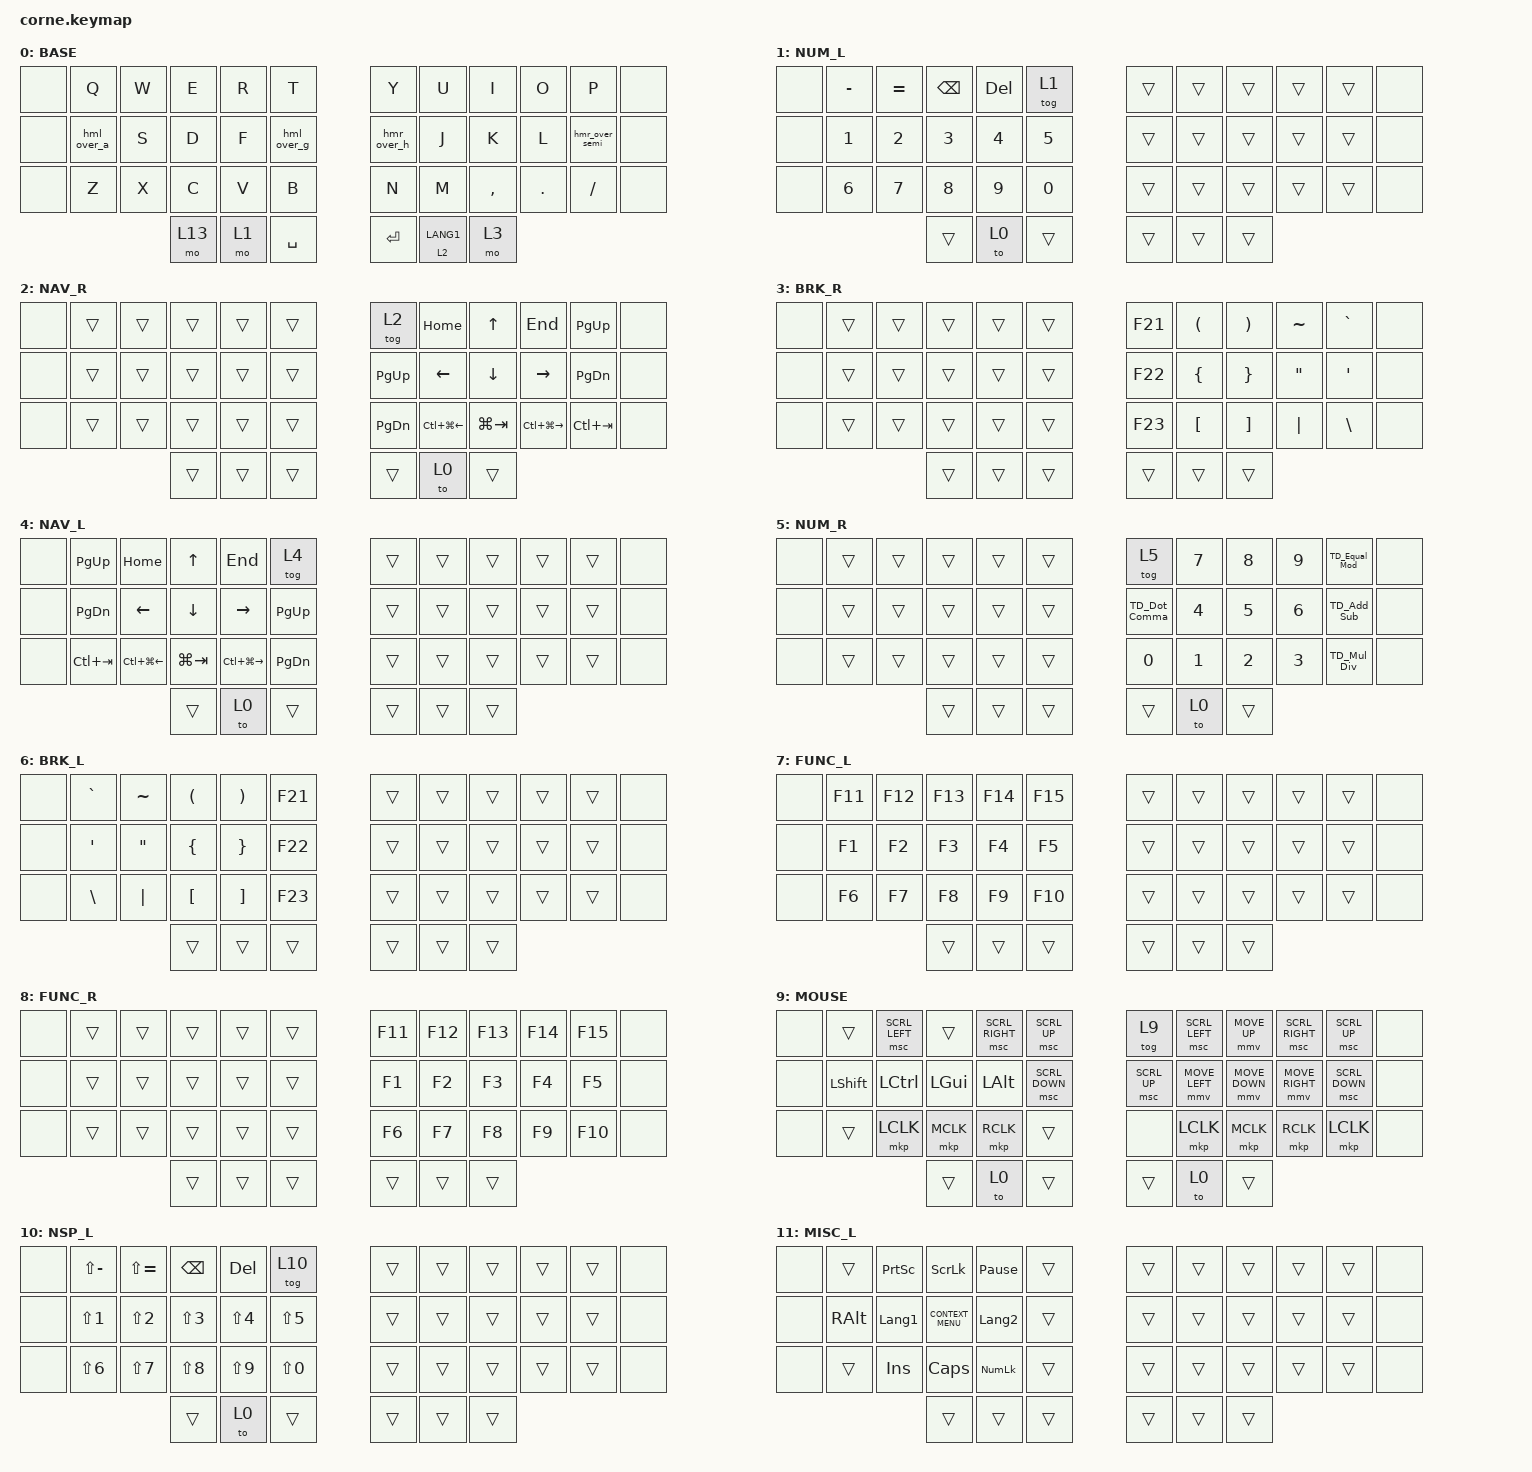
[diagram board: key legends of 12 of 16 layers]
/*
 * Copyright (c) 2020 The ZMK Contributors
 *
 * SPDX-License-Identifier: MIT
 */

#include <behaviors.dtsi>
#include <dt-bindings/zmk/bt.h>
#include <dt-bindings/zmk/ext_power.h>
#include <dt-bindings/zmk/keys.h>
#include <dt-bindings/zmk/outputs.h>
#include <dt-bindings/zmk/pointing.h>

&mt {
    flavor = "balanced";
    quick-tap-ms = <175>;
};

&lt {
    flavor = "hold-preferred";
    tapping-term-ms = <180>;
    hold-while-undecided;
};

&tog { toggle-mode = "on"; };

/ {
    combos {
        compatible = "zmk,combos";

        CAPS_L {
            bindings = <&kp CAPSLOCK>;
            key-positions = <27 37>;
            layers = <0>;
            require-prior-idle-ms = <0>;
            timeout-ms = <30>;
        };

        TAB_L {
            bindings = <&kp TAB>;
            key-positions = <17 38>;
            layers = <0>;
            require-prior-idle-ms = <0>;
            timeout-ms = <30>;
        };

        ENTER_L {
            bindings = <&kp ENTER>;
            key-positions = <5 38>;
            layers = <0>;
            require-prior-idle-ms = <0>;
            timeout-ms = <30>;
        };

        ESC_L {
            bindings = <&kp ESCAPE>;
            key-positions = <37 2>;
            layers = <0>;
            require-prior-idle-ms = <0>;
            timeout-ms = <30>;
        };

        VOL_UP_L {
            bindings = <&kp C_VOLUME_UP>;
            key-positions = <37 5>;
            layers = <0>;
            require-prior-idle-ms = <200>;
            timeout-ms = <30>;
        };

        VOL_DN_L {
            bindings = <&kp C_VOLUME_DOWN>;
            key-positions = <37 17>;
            layers = <0>;
            require-prior-idle-ms = <200>;
            timeout-ms = <30>;
        };

        LCtrl_L {
            bindings = <&kp LEFT_CONTROL>;
            key-positions = <14 15>;
            layers = <0>;
            slow-release;
            require-prior-idle-ms = <70>;
            timeout-ms = <30>;
        };

        LAlt_L {
            bindings = <&kp LEFT_ALT>;
            key-positions = <16 17>;
            layers = <0>;
            slow-release;
            require-prior-idle-ms = <70>;
            timeout-ms = <30>;
        };

        LGUI_L {
            bindings = <&kp LEFT_GUI>;
            key-positions = <16 15>;
            layers = <0>;
            slow-release;
            require-prior-idle-ms = <70>;
            timeout-ms = <30>;
        };

        MO_FUNC_L {
            bindings = <&mo 7>;
            key-positions = <37 16>;
            layers = <0 2 3 5 8 12>;
            slow-release;
            require-prior-idle-ms = <0>;
            timeout-ms = <30>;
        };

        MO_FUNC_R {
            bindings = <&mo 8>;
            key-positions = <40 19>;
            layers = <0 1 4 6 7 10 11>;
            slow-release;
            require-prior-idle-ms = <0>;
            timeout-ms = <30>;
        };

        MO_NAV_L {
            bindings = <&mo 4>;
            key-positions = <15 37>;
            layers = <0 2 3 5 8 12>;
            slow-release;
            require-prior-idle-ms = <0>;
            timeout-ms = <30>;
        };

        MO_NUM_R {
            bindings = <&mo 5>;
            key-positions = <40 20>;
            layers = <0 1 4 6 7 10 11>;
            slow-release;
            timeout-ms = <30>;
        };

        MO_MISC_L {
            bindings = <&mo 11>;
            key-positions = <37 14>;
            layers = <0 2 3 5 8 12>;
            slow-release;
            require-prior-idle-ms = <0>;
            timeout-ms = <30>;
        };

        MO_MISC_R {
            bindings = <&mo 12>;
            key-positions = <40 21>;
            layers = <0 1 4 6 7 10 11>;
            slow-release;
            require-prior-idle-ms = <0>;
            timeout-ms = <30>;
        };

        MO_BRK_L {
            bindings = <&mo 6>;
            key-positions = <37 29>;
            layers = <0 2 3 5 8 12>;
            slow-release;
            require-prior-idle-ms = <0>;
            timeout-ms = <30>;
        };

        MO_NUMSP_L {
            bindings = <&mo 10>;
            key-positions = <37 28>;
            layers = <0 2 3 5 8 12>;
            slow-release;
            require-prior-idle-ms = <0>;
            timeout-ms = <30>;
        };

        MO_MOUSE {
            bindings = <&mo 9>;
            key-positions = <40 31>;
            layers = <0>;
            slow-release;
            require-prior-idle-ms = <200>;
            timeout-ms = <30>;
        };

        TO_BASE_L {
            bindings = <&to 0>;
            key-positions = <38 37 36>;
            timeout-ms = <30>;
        };

        MO_SETTING {
            bindings = <&mo 14>;
            key-positions = <14 3 5 37>;
            require-prior-idle-ms = <0>;
            slow-release;
            timeout-ms = <30>;
        };

        bootload {
            bindings = <&bootloader>;
            key-positions = <5 29 29>;
            layers = <14>;
        };

        sysreset {
            bindings = <&sys_reset>;
            key-positions = <4 14>;
            layers = <14>;
        };

        LCTRL_SHFT_L {
            bindings = <&kp LC(LEFT_SHIFT)>;
            key-positions = <14 13>;
            slow-release;
            layers = <0>;
            require-prior-idle-ms = <70>;
            timeout-ms = <30>;
        };

        LALT_SHFT_L {
            bindings = <&kp LA(LEFT_SHIFT)>;
            key-positions = <13 16>;
            slow-release;
            layers = <0>;
            require-prior-idle-ms = <70>;
            timeout-ms = <30>;
        };

        LCTRL_ALT_L {
            bindings = <&kp LC(LEFT_ALT)>;
            key-positions = <14 17>;
            slow-release;
            layers = <0 9>;
            require-prior-idle-ms = <70>;
            timeout-ms = <30>;
        };

        LGUI_SHFT_L {
            bindings = <&kp LG(LEFT_SHIFT)>;
            key-positions = <13 15>;
            slow-release;
            layers = <0>;
            require-prior-idle-ms = <70>;
            timeout-ms = <30>;
        };

        LGUI_CTRL_L {
            bindings = <&kp LC(LGUI)>;
            key-positions = <14 16>;
            slow-release;
            layers = <0>;
            require-prior-idle-ms = <70>;
            timeout-ms = <30>;
        };

        TO_BASE_R {
            bindings = <&to 0>;
            key-positions = <39 40 41>;
            timeout-ms = <30>;
        };

        B_R {
            bindings = <&kp B>;
            key-positions = <30 31>;
            layers = <0>;
            timeout-ms = <30>;
        };

        SHFT_P_R {
            bindings = <&kp LS(P)>;
            key-positions = <21 7>;
            layers = <0>;
            require-prior-idle-ms = <0>;
            timeout-ms = <30>;
        };

        P_R {
            bindings = <&kp P>;
            key-positions = <21 19>;
            layers = <0>;
            timeout-ms = <30>;
        };

        LGUI_ALT_L {
            bindings = <&kp LA(LGUI)>;
            key-positions = <15 17>;
            slow-release;
            require-prior-idle-ms = <70>;
            layers = <0>;
            timeout-ms = <30>;
        };

        LCAG_L {
            bindings = <&kp LC(LA(LEFT_GUI))>;
            key-positions = <14 15 16>;
            timeout-ms = <30>;
            slow-release;
            require-prior-idle-ms = <70>;
            layers = <0>;
        };

        O_R {
            bindings = <&kp O>;
            key-positions = <21 20>;
            timeout-ms = <30>;
            layers = <0>;
        };

        SHFT_O_R {
            bindings = <&kp RS(O)>;
            key-positions = <21 8>;
            timeout-ms = <30>;
            layers = <0>;
        };

        MENU_R {
            bindings = <&kp K_CONTEXT_MENU>;
            key-positions = <40 32>;
            timeout-ms = <30>;
            layers = <0>;
        };

        LANG2_R {
            bindings = <&kp LANG2>;
            key-positions = <40 33>;
            timeout-ms = <30>;
            layers = <0>;
        };

        RALT_L {
            bindings = <&kp LANG1>;
            key-positions = <27 26>;
            timeout-ms = <30>;
            layers = <0>;
        };

        MO_CUSTOM_L {
            bindings = <&mo 15>;
            key-positions = <37 1>;
            layers = <0>;
            slow-release;
            timeout-ms = <30>;
        };
    };

    behaviors {
        TD_Dot_Comma: TD_Dot_Comma {
            compatible = "zmk,behavior-tap-dance";
            label = "TD_DOT_COMMA";
            #binding-cells = <0>;
            bindings = <&kp KP_DOT>, <&kp KP_COMMA>;

            tapping-term-ms = <180>;
        };

        TD_Add_Sub: TD_Add_Sub {
            compatible = "zmk,behavior-tap-dance";
            label = "TD_ADD_SUB";
            #binding-cells = <0>;
            bindings = <&kp PLUS>, <&kp MINUS>;

            tapping-term-ms = <180>;
        };

        TD_Mul_Div: TD_Mul_Div {
            compatible = "zmk,behavior-tap-dance";
            label = "TD_MUL_DIV";
            #binding-cells = <0>;
            bindings = <&kp ASTERISK>, <&kp SLASH>;

            tapping-term-ms = <180>;
        };

        ht: ht {
            compatible = "zmk,behavior-hold-tap";
            label = "ht homerow";
            bindings = <&kp>, <&kp>;

            #binding-cells = <2>;
            tapping-term-ms = <200>;
            quick-tap-ms = <130>;
            flavor = "tap-preferred";
        };

        hml: hml {
            compatible = "zmk,behavior-hold-tap";
            label = "HML";
            bindings = <&kp>, <&kp>;

            #binding-cells = <2>;
            tapping-term-ms = <165>;
            flavor = "balanced";
        };

        hmr: hmr {
            compatible = "zmk,behavior-hold-tap";
            label = "HMR ";
            bindings = <&kp>, <&kp>;

            #binding-cells = <2>;
            tapping-term-ms = <165>;
            flavor = "balanced";
        };

        lt_spc: lt_spc {
            compatible = "zmk,behavior-hold-tap";
            label = "LT_SPC";
            bindings = <&mo>, <&kp>;

            #binding-cells = <2>;
            tapping-term-ms = <250>;
            flavor = "tap-preferred";
            quick-tap-ms = <200>;
            require-prior-idle-ms = <250>;
        };

        TD_Equal_Mod: TD_Equal_Mod {
            compatible = "zmk,behavior-tap-dance";
            label = "TD_EQUAL_MOD";
            #binding-cells = <0>;
            bindings = <&kp EQUAL>, <&kp PERCENT>;

            tapping-term-ms = <180>;
        };

        hml_over_a: hml_over_a {
            compatible = "zmk,behavior-mod-morph";
            label = "HML_OVER_A";
            bindings = <&hml LSHFT A>, <&kp A>;

            #binding-cells = <0>;
            mods = <(MOD_RSFT|MOD_LSFT)>;
            keep-mods = <(MOD_RSFT|MOD_LSFT)>;
        };

        hml_over_g: hml_over_g {
            compatible = "zmk,behavior-mod-morph";
            label = "HML_OVER_G";
            bindings = <&hml LSHFT G>, <&kp G>;

            #binding-cells = <0>;
            mods = <(MOD_RSFT|MOD_LSFT)>;
            keep-mods = <(MOD_LSFT|MOD_RSFT)>;
        };

        hmr_over_semi: hmr_over_semi {
            compatible = "zmk,behavior-mod-morph";
            label = "HMR_OVER_SEMI";
            bindings = <&hmr RSHFT SEMICOLON>, <&kp SEMICOLON>;

            #binding-cells = <0>;
            mods = <(MOD_RSFT|MOD_LSFT)>;
            keep-mods = <(MOD_LSFT|MOD_RSFT)>;
        };

        hmr_over_h: hmr_over_h {
            compatible = "zmk,behavior-mod-morph";
            label = "HMR_OVER_H";
            bindings = <&hmr RSHFT H>, <&kp H>;

            #binding-cells = <0>;
            mods = <(MOD_RSFT|MOD_LSFT)>;
            keep-mods = <(MOD_LSFT|MOD_RSFT)>;
        };
    };

    keymap {
        compatible = "zmk,keymap";

        BASE_LR {
            // -----------------------------------------------------------------------------------------
            // |  TAB |  Q  |  W  |  E  |  R  |  T  |   |  Y  |  U   |  I  |  O  |  P  | BKSP |
            // | CTRL |  A  |  S  |  D  |  F  |  G  |   |  H  |  J   |  K  |  L  |  ;  |  '   |
            // | SHFT |  Z  |  X  |  C  |  V  |  B  |   |  N  |  M   |  ,  |  .  |  /  | ESC  |
            //                    | GUI | LWR | SPC |   | ENT | RSE  | ALT |

            display-name = "BASE";
            bindings = <
&none  &kp Q        &kp W  &kp E   &kp R  &kp T          &kp Y        &kp U        &kp I      &kp O    &kp P           &none
&none  &hml_over_a  &kp S  &kp D   &kp F  &hml_over_g    &hmr_over_h  &kp J        &kp K      &kp L    &hmr_over_semi  &none
&none  &kp Z        &kp X  &kp C   &kp V  &kp B          &kp N        &kp M        &kp COMMA  &kp DOT  &kp SLASH       &none
                           &mo 13  &mo 1  &kp SPACE      &kp RET      &lt 2 LANG1  &mo 3
            >;
        };

        NUM_L {
            display-name = "NUM_L";
            bindings = <
&none  &kp MINUS     &kp EQUAL     &kp BACKSPACE  &kp DELETE    &tog 1          &trans  &trans  &trans  &trans  &trans  &none
&none  &kp NUMBER_1  &kp NUMBER_2  &kp NUMBER_3   &kp NUMBER_4  &kp NUMBER_5    &trans  &trans  &trans  &trans  &trans  &none
&none  &kp NUMBER_6  &kp NUMBER_7  &kp NUMBER_8   &kp NUMBER_9  &kp NUMBER_0    &trans  &trans  &trans  &trans  &trans  &none
                                   &trans         &to 0         &trans          &trans  &trans  &trans
            >;
        };

        NAV_R {
            display-name = "NAV_R";
            bindings = <
&none  &trans  &trans  &trans  &trans  &trans    &tog 2       &kp HOME          &kp UP_ARROW    &kp END            &kp PG_UP      &none
&none  &trans  &trans  &trans  &trans  &trans    &kp PAGE_UP  &kp LEFT_ARROW    &kp DOWN_ARROW  &kp RIGHT_ARROW    &kp PAGE_DOWN  &none
&none  &trans  &trans  &trans  &trans  &trans    &kp PG_DN    &kp LC(LG(LEFT))  &kp LG(TAB)     &kp LC(LG(RIGHT))  &kp LC(TAB)    &none
                       &trans  &trans  &trans    &trans       &to 0             &trans
            >;
        };

        BRK_R {
            display-name = "BRK_R";
            bindings = <
&none  &trans  &trans  &trans  &trans  &trans    &kp F21  &kp LEFT_PARENTHESIS  &kp RIGHT_PARENTHESIS  &kp TILDE          &kp GRAVE         &none
&none  &trans  &trans  &trans  &trans  &trans    &kp F22  &kp LEFT_BRACE        &kp RIGHT_BRACE        &kp DOUBLE_QUOTES  &kp SINGLE_QUOTE  &none
&none  &trans  &trans  &trans  &trans  &trans    &kp F23  &kp LEFT_BRACKET      &kp RIGHT_BRACKET      &kp PIPE           &kp BACKSLASH     &none
                       &trans  &trans  &trans    &trans   &trans                &trans
            >;
        };

        NAV_L {
            display-name = "NAV_L";
            bindings = <
&none  &kp PG_UP      &kp HOME          &kp UP_ARROW    &kp END            &tog 4           &trans  &trans  &trans  &trans  &trans  &none
&none  &kp PAGE_DOWN  &kp LEFT_ARROW    &kp DOWN_ARROW  &kp RIGHT_ARROW    &kp PG_UP        &trans  &trans  &trans  &trans  &trans  &none
&none  &kp LC(TAB)    &kp LC(LG(LEFT))  &kp LG(TAB)     &kp LC(LG(RIGHT))  &kp PAGE_DOWN    &trans  &trans  &trans  &trans  &trans  &none
                                        &trans          &to 0              &trans           &trans  &trans  &trans
            >;
        };

        NUM_R {
            display-name = "NUM_R";
            bindings = <
&none  &trans  &trans  &trans  &trans  &trans    &tog 5         &kp NUMBER_7  &kp NUMBER_8  &kp NUMBER_9  &TD_Equal_Mod  &none
&none  &trans  &trans  &trans  &trans  &trans    &TD_Dot_Comma  &kp NUMBER_4  &kp NUMBER_5  &kp NUMBER_6  &TD_Add_Sub    &none
&none  &trans  &trans  &trans  &trans  &trans    &kp NUMBER_0   &kp NUMBER_1  &kp NUMBER_2  &kp NUMBER_3  &TD_Mul_Div    &none
                       &trans  &trans  &trans    &trans         &to 0         &trans
            >;
        };

        BRK_L {
            display-name = "BRK_L";
            bindings = <
&none  &kp GRAVE         &kp TILDE          &kp LEFT_PARENTHESIS  &kp RIGHT_PARENTHESIS  &kp F21    &trans  &trans  &trans  &trans  &trans  &none
&none  &kp SINGLE_QUOTE  &kp DOUBLE_QUOTES  &kp LEFT_BRACE        &kp RIGHT_BRACE        &kp F22    &trans  &trans  &trans  &trans  &trans  &none
&none  &kp BACKSLASH     &kp PIPE           &kp LEFT_BRACKET      &kp RIGHT_BRACKET      &kp F23    &trans  &trans  &trans  &trans  &trans  &none
                                            &trans                &trans                 &trans     &trans  &trans  &trans
            >;
        };

        FUNC_L {
            display-name = "FUNC_L";
            bindings = <
&none  &kp F11  &kp F12  &kp F13  &kp F14  &kp F15    &trans  &trans  &trans  &trans  &trans  &none
&none  &kp F1   &kp F2   &kp F3   &kp F4   &kp F5     &trans  &trans  &trans  &trans  &trans  &none
&none  &kp F6   &kp F7   &kp F8   &kp F9   &kp F10    &trans  &trans  &trans  &trans  &trans  &none
                         &trans   &trans   &trans     &trans  &trans  &trans
            >;
        };

        FUNC_R {
            display-name = "FUNC_R";
            bindings = <
&none  &trans  &trans  &trans  &trans  &trans    &kp F11  &kp F12  &kp F13  &kp F14  &kp F15  &none
&none  &trans  &trans  &trans  &trans  &trans    &kp F1   &kp F2   &kp F3   &kp F4   &kp F5   &none
&none  &trans  &trans  &trans  &trans  &trans    &kp F6   &kp F7   &kp F8   &kp F9   &kp F10  &none
                       &trans  &trans  &trans    &trans   &trans   &trans
            >;
        };

        MOUSE_LR {
            display-name = "MOUSE";
            bindings = <
&none  &trans     &msc SCRL_LEFT  &trans        &msc SCRL_RIGHT  &msc SCRL_UP      &tog 9        &msc SCRL_LEFT  &mmv MOVE_UP    &msc SCRL_RIGHT  &msc SCRL_UP    &none
&none  &kp LSHFT  &kp LCTRL       &kp LEFT_GUI  &kp LALT         &msc SCRL_DOWN    &msc SCRL_UP  &mmv MOVE_LEFT  &mmv MOVE_DOWN  &mmv MOVE_RIGHT  &msc SCRL_DOWN  &none
&none  &trans     &mkp LCLK       &mkp MCLK     &mkp RCLK        &trans            &none         &mkp LCLK       &mkp MCLK       &mkp RCLK        &mkp LCLK       &none
                                  &trans        &to 0            &trans            &trans        &to 0           &trans
            >;
        };

        NUMSP_L {
            display-name = "NSP_L";
            bindings = <
&none  &kp LS(MINUS)     &kp LS(EQUAL)     &kp BACKSPACE     &kp DELETE        &tog 10             &trans  &trans  &trans  &trans  &trans  &none
&none  &kp LS(NUMBER_1)  &kp LS(NUMBER_2)  &kp LS(NUMBER_3)  &kp LS(NUMBER_4)  &kp LS(NUMBER_5)    &trans  &trans  &trans  &trans  &trans  &none
&none  &kp LS(NUMBER_6)  &kp LS(NUMBER_7)  &kp LS(NUMBER_8)  &kp LS(NUMBER_9)  &kp LS(NUMBER_0)    &trans  &trans  &trans  &trans  &trans  &none
                                           &trans            &to 0             &trans              &trans  &trans  &trans
            >;
        };

        MISC_L {
            display-name = "MISC_L";
            bindings = <
&none  &trans         &kp PRINTSCREEN  &kp SCROLLLOCK      &kp PAUSE_BREAK  &trans    &trans  &trans  &trans  &trans  &trans  &none
&none  &kp RIGHT_ALT  &kp LANGUAGE_1   &kp K_CONTEXT_MENU  &kp LANGUAGE_2   &trans    &trans  &trans  &trans  &trans  &trans  &none
&none  &trans         &kp INS          &kp CAPS            &kp KP_NUMLOCK   &trans    &trans  &trans  &trans  &trans  &trans  &none
                                       &trans              &trans           &trans    &trans  &trans  &trans
            >;
        };

        MISC_R {
            display-name = "MISC_R";
            bindings = <
&none  &trans  &trans  &trans  &trans  &trans    &none   &kp PAUSE_BREAK  &kp SCROLLLOCK      &kp PRINTSCREEN  &none     &none
&none  &trans  &trans  &trans  &trans  &trans    &none   &kp LANGUAGE_2   &kp K_CONTEXT_MENU  &kp LANGUAGE_1   &kp RALT  &none
&none  &trans  &trans  &trans  &trans  &trans    &none   &kp KP_NUMLOCK   &kp CAPS            &kp INS          &none     &none
                       &trans  &trans  &trans    &trans  &trans           &trans
            >;
        };

        MIRROR_L {
            display-name = "MIRROR";
            bindings = <
&none  &kp P           &kp O       &kp I      &kp U   &kp Y          &trans  &trans  &trans  &trans  &trans  &none
&none  &hmr_over_semi  &kp L       &kp K      &kp J   &hmr_over_h    &trans  &trans  &trans  &trans  &trans  &none
&none  &kp SLASH       &kp PERIOD  &kp COMMA  &kp M   &kp N          &trans  &trans  &trans  &trans  &trans  &none
                                   &trans     &trans  &trans         &trans  &trans  &trans
            >;
        };

        SETTING_LR {
            display-name = "SET";
            bindings = <
&none  &bt BT_DISC 0  &bt BT_DISC 1  &bt BT_DISC 2      &bt BT_DISC 3  &bt BT_DISC 4     &none      &none   &none   &none  &none  &none
&none  &bt BT_SEL 0   &bt BT_SEL 1   &bt BT_SEL 2       &bt BT_SEL 3   &bt BT_SEL 4      &none      &none   &none   &none  &none  &none
&none  &bt BT_CLR     &bt BT_PRV     &bt BT_NXT         &out OUT_TOG   &bt BT_CLR_ALL    &none      &none   &none   &none  &none  &none
                                     &ext_power EP_TOG  &trans         &kp SPACE         &kp ENTER  &trans  &trans
            >;
        };

        CUSTOM_L {
            bindings = <
&trans  &kp F24  &kp F21  &kp F18  &kp F15  &kp C_VOL_UP    &trans  &trans  &trans  &trans  &trans  &trans
&trans  &kp F23  &kp F20  &kp F17  &kp F14  &kp C_VOL_DN    &trans  &trans  &trans  &trans  &trans  &trans
&trans  &kp F22  &kp F19  &kp F16  &kp F13  &kp K_MUTE      &trans  &trans  &trans  &trans  &trans  &trans
                          &trans   &trans   &trans          &trans  &trans  &trans
            >;

            label = "CUSTOM";
        };
    };

    conditional_layers { compatible = "zmk,conditional-layers"; };
};
